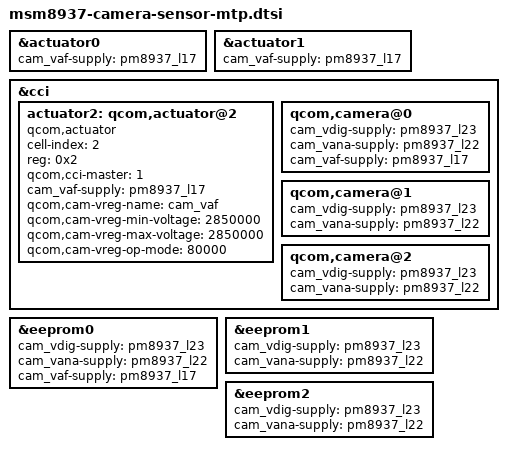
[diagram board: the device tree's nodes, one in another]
/*
 * Copyright (c) 2015-2018, The Linux Foundation. All rights reserved.
 *
 * This program is free software; you can redistribute it and/or modify
 * it under the terms of the GNU General Public License version 2 and
 * only version 2 as published by the Free Software Foundation.
 *
 * This program is distributed in the hope that it will be useful,
 * but WITHOUT ANY WARRANTY; without even the implied warranty of
 * MERCHANTABILITY or FITNESS FOR A PARTICULAR PURPOSE.  See the
 * GNU General Public License for more details.
 */

&actuator0 {
	cam_vaf-supply = <&pm8937_l17>;
};

&actuator1 {
	cam_vaf-supply = <&pm8937_l17>;
};

&cci {
	actuator2: qcom,actuator@2 {
		cell-index = <2>;
		reg = <0x2>;
		compatible = "qcom,actuator";
		qcom,cci-master = <1>;
		cam_vaf-supply = <&pm8937_l17>;
		qcom,cam-vreg-name = "cam_vaf";
		qcom,cam-vreg-min-voltage = <2850000>;
		qcom,cam-vreg-max-voltage = <2850000>;
		qcom,cam-vreg-op-mode = <80000>;
	};
};

&eeprom0 {
	cam_vdig-supply = <&pm8937_l23>;
	cam_vana-supply = <&pm8937_l22>;
	cam_vaf-supply = <&pm8937_l17>;
};

&eeprom1 {
	cam_vdig-supply = <&pm8937_l23>;
	cam_vana-supply = <&pm8937_l22>;
};

&eeprom2 {
	cam_vdig-supply = <&pm8937_l23>;
	cam_vana-supply = <&pm8937_l22>;
};

&cci {
	qcom,camera@0 {
		cam_vdig-supply = <&pm8937_l23>;
		cam_vana-supply = <&pm8937_l22>;
		cam_vaf-supply = <&pm8937_l17>;
	};

	qcom,camera@1 {
		cam_vdig-supply = <&pm8937_l23>;
		cam_vana-supply = <&pm8937_l22>;
	};

	qcom,camera@2 {
		cam_vdig-supply = <&pm8937_l23>;
		cam_vana-supply = <&pm8937_l22>;
	};
};
